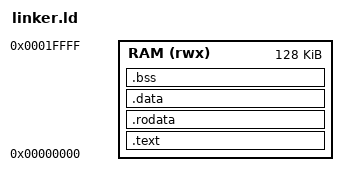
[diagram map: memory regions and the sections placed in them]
ENTRY(_start)

MEMORY {
    RAM (rwx) : ORIGIN = 0x00000000, LENGTH = 128K
}

SECTIONS {
    .text : {
        *(.text._start)
        *(.text .text.*)
    } > RAM

    .rodata : {
        *(.rodata .rodata.*)
    } > RAM

    .data : {
        *(.data .data.*)
    } > RAM

    .bss : {
        __bss_start = .;
        *(.bss .bss.*)
        *(COMMON)
        __bss_end = .;
    } > RAM

    __stack_top = ORIGIN(RAM) + LENGTH(RAM);

    /DISCARD/ : {
        *(.comment)
        *(.eh_frame)
        *(.riscv.attributes)
    }
}
